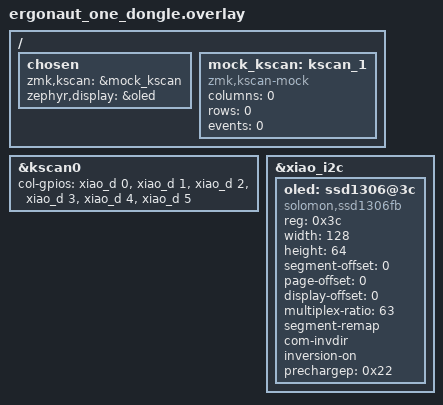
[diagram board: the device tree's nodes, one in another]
/*
 * Copyright (c) 2020 The ZMK Contributors
 *
 * SPDX-License-Identifier: MIT
 */

#include "ergonaut_one.dtsi"
/ {
    chosen {
        zmk,kscan = &mock_kscan;
        zephyr,display = &oled;
    };

    mock_kscan: kscan_1 {
        compatible = "zmk,kscan-mock";
        columns = <0>;
        rows = <0>;
        events = <0>;
    };
};

&kscan0 {
    col-gpios
        = <&xiao_d 0 GPIO_ACTIVE_HIGH>
        , <&xiao_d 1 GPIO_ACTIVE_HIGH>
        , <&xiao_d 2 GPIO_ACTIVE_HIGH>
        , <&xiao_d 3 GPIO_ACTIVE_HIGH>
        , <&xiao_d 4 GPIO_ACTIVE_HIGH>
        , <&xiao_d 5 GPIO_ACTIVE_HIGH>
        ;
};

&xiao_i2c {
    status = "okay";
    
    oled: ssd1306@3c {
        compatible = "solomon,ssd1306fb";
        reg = <0x3c>;
        width = <128>;
        height = <64>;
        segment-offset = <0>;
        page-offset = <0>;
        display-offset = <0>;
        multiplex-ratio = <63>;
        segment-remap;
        com-invdir;
        inversion-on;
        prechargep = <0x22>;
    };
};
